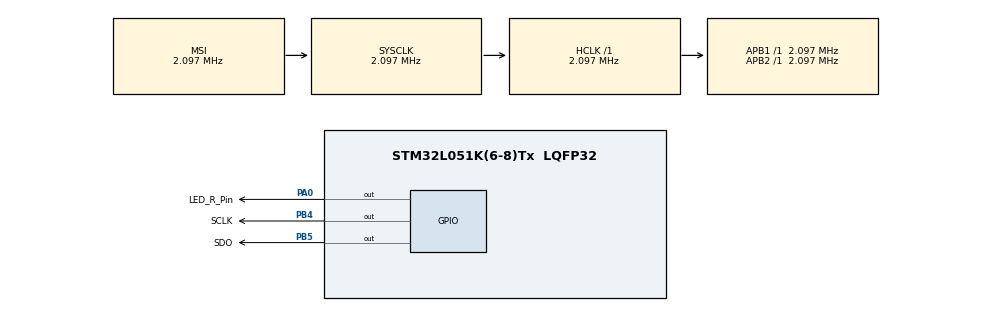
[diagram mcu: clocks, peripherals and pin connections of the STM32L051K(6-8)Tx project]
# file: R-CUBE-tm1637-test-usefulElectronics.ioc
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Mcu.Family=STM32L0
Mcu.Name=STM32L051K(6-8)Tx
Mcu.Package=LQFP32
PA0.GPIO_Label=LED_R_Pin
PA0.Signal=GPIO_Output
PA13.Mode=Serial_Wire
PA13.Signal=SYS_SWDIO
PA14.Mode=Serial_Wire
PA14.Signal=SYS_SWCLK
PB4.GPIO_Label=SCLK
PB4.Signal=GPIO_Output
PB5.GPIO_Label=SDO
PB5.Signal=GPIO_Output
ProjectManager.HeapSize=0x200
ProjectManager.StackSize=0x400
ProjectManager.TargetToolchain=STM32CubeIDE
RCC.AHBFreq_Value=2097000
RCC.APB1Freq_Value=2097000
RCC.APB1TimFreq_Value=2097000
RCC.APB2Freq_Value=2097000
RCC.APB2TimFreq_Value=2097000
RCC.HSI16_VALUE=16000000
RCC.HSI_VALUE=16000000
RCC.LSE_VALUE=32768
RCC.MSI_VALUE=2097000
RCC.SYSCLKFreq_VALUE=2097000
RCC.VCOOutputFreq_Value=48000000
board=custom

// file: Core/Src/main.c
/* USER CODE BEGIN Header */
/**
  ******************************************************************************
  * @file           : main.c
  * @brief          : Main program body
  ******************************************************************************
  * @attention
  *
  * Copyright (c) 2022 STMicroelectronics.
  * All rights reserved.
  *
  * This software is licensed under terms that can be found in the LICENSE file
  * in the root directory of this software component.
  * If no LICENSE file comes with this software, it is provided AS-IS.
  *
  ******************************************************************************
  */
/* USER CODE END Header */
#include "main.h"

/* USER CODE BEGIN Includes */
#include "TM1637.h"
/* USER CODE END Includes */

void SystemClock_Config(void);
static void MX_GPIO_Init(void);

/* USER CODE BEGIN 0 */
uint8_t	Timer1Enable = ENABLE;
uint32_t Timer1  = 0;
uint8_t CurrentDisplay[4] = {0};
uint8_t tm1637_Segments[8] = {0};
/* USER CODE END 0 */

int main(void)
{
  /* USER CODE BEGIN 1 */
	//DP is connected to the second digit MSB
	  tm1637_Segments[0] = A_SEG;
	  tm1637_Segments[1] = B_SEG;
	  tm1637_Segments[2] = C_SEG;
	  tm1637_Segments[3] = D_SEG;
	  tm1637_Segments[4] = E_SEG;
	  tm1637_Segments[5] = F_SEG;
	  tm1637_Segments[6] = G_SEG;
	  tm1637_Segments[7] = DP_SEG;
  /* USER CODE END 1 */

  /* MCU Configuration--------------------------------------------------------*/

  /* Reset of all peripherals, Initializes the Flash interface and the Systick. */
  HAL_Init();

  /* Configure the system clock */
  SystemClock_Config();

  /* Initialize all configured peripherals */
  MX_GPIO_Init();
  /* USER CODE BEGIN 2 */
  HAL_GPIO_WritePin(SCLK_GPIO_Port, SCLK_Pin, GPIO_PIN_SET);
    HAL_GPIO_WritePin(SDO_GPIO_Port, SDO_Pin, GPIO_PIN_SET);
    HAL_GPIO_WritePin(LED_R_Pin_GPIO_Port, LED_R_Pin_Pin, GPIO_PIN_SET);

    tm1637_DisplayHandle(7, CurrentDisplay);						//

    Timer1Enable = ENABLE;
  /* USER CODE END 2 */

  /* Infinite loop */
  /* USER CODE BEGIN WHILE */
  while (1)
  {
	  if(HAL_GetTick() >= 10000)
	  	  {
	  		  tm1637_DisplayClear();
	  	  }
	  	  else
	  	  {
	  		  tm1637_Effect(80);
	  	  }
    /* USER CODE END WHILE */

  }
}

void SystemClock_Config(void)
{
  RCC_OscInitTypeDef RCC_OscInitStruct = {0};
  RCC_ClkInitTypeDef RCC_ClkInitStruct = {0};

  /** Configure the main internal regulator output voltage
  */
  __HAL_PWR_VOLTAGESCALING_CONFIG(PWR_REGULATOR_VOLTAGE_SCALE1);
  /** Initializes the RCC Oscillators according to the specified parameters
  * in the RCC_OscInitTypeDef structure.
  */
  RCC_OscInitStruct.OscillatorType = RCC_OSCILLATORTYPE_MSI;
  RCC_OscInitStruct.MSIState = RCC_MSI_ON;
  RCC_OscInitStruct.MSICalibrationValue = 0;
  RCC_OscInitStruct.MSIClockRange = RCC_MSIRANGE_5;
  RCC_OscInitStruct.PLL.PLLState = RCC_PLL_NONE;
  if (HAL_RCC_OscConfig(&RCC_OscInitStruct) != HAL_OK)
  {
    Error_Handler();
  }
  /** Initializes the CPU, AHB and APB buses clocks
  */
  RCC_ClkInitStruct.ClockType = RCC_CLOCKTYPE_HCLK|RCC_CLOCKTYPE_SYSCLK
                              |RCC_CLOCKTYPE_PCLK1|RCC_CLOCKTYPE_PCLK2;
  RCC_ClkInitStruct.SYSCLKSource = RCC_SYSCLKSOURCE_MSI;
  RCC_ClkInitStruct.AHBCLKDivider = RCC_SYSCLK_DIV1;
  RCC_ClkInitStruct.APB1CLKDivider = RCC_HCLK_DIV1;
  RCC_ClkInitStruct.APB2CLKDivider = RCC_HCLK_DIV1;

  if (HAL_RCC_ClockConfig(&RCC_ClkInitStruct, FLASH_LATENCY_0) != HAL_OK)
  {
    Error_Handler();
  }
}

static void MX_GPIO_Init(void)
{
  GPIO_InitTypeDef GPIO_InitStruct = {0};

  /* GPIO Ports Clock Enable */
  __HAL_RCC_GPIOA_CLK_ENABLE();
  __HAL_RCC_GPIOB_CLK_ENABLE();

  /*Configure GPIO pin Output Level */
  HAL_GPIO_WritePin(LED_R_Pin_GPIO_Port, LED_R_Pin_Pin, GPIO_PIN_RESET);

  /*Configure GPIO pin Output Level */
  HAL_GPIO_WritePin(GPIOB, SCLK_Pin|SDO_Pin, GPIO_PIN_RESET);

  /*Configure GPIO pin : LED_R_Pin_Pin */
  GPIO_InitStruct.Pin = LED_R_Pin_Pin;
  GPIO_InitStruct.Mode = GPIO_MODE_OUTPUT_PP;
  GPIO_InitStruct.Pull = GPIO_NOPULL;
  GPIO_InitStruct.Speed = GPIO_SPEED_FREQ_LOW;
  HAL_GPIO_Init(LED_R_Pin_GPIO_Port, &GPIO_InitStruct);

  /*Configure GPIO pins : SCLK_Pin SDO_Pin */
  GPIO_InitStruct.Pin = SCLK_Pin|SDO_Pin;
  GPIO_InitStruct.Mode = GPIO_MODE_OUTPUT_PP;
  GPIO_InitStruct.Pull = GPIO_NOPULL;
  GPIO_InitStruct.Speed = GPIO_SPEED_FREQ_LOW;
  HAL_GPIO_Init(GPIOB, &GPIO_InitStruct);

}

void Error_Handler(void)
{
  __disable_irq();
  while (1)
  {
  }
}
